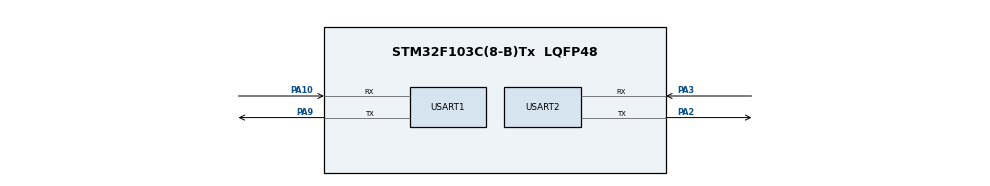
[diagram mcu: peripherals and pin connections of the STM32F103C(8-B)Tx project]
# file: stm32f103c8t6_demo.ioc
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Mcu.Family=STM32F1
Dma.USART2_RX.2.PeriphDataAlignment=DMA_PDATAALIGN_BYTE
Dma.USART2_TX.3.MemDataAlignment=DMA_MDATAALIGN_BYTE
NVIC.DMA1_Channel6_IRQn=true\:0\:0\:false\:false\:true\:false\:true
Dma.USART1_TX.1.Instance=DMA1_Channel4
NVIC.DMA1_Channel5_IRQn=true\:0\:0\:false\:false\:true\:false\:true
Dma.USART1_RX.0.PeriphDataAlignment=DMA_PDATAALIGN_BYTE
PA10.Mode=Asynchronous
Dma.USART1_TX.1.MemInc=DMA_MINC_ENABLE
Dma.USART2_TX.3.Instance=DMA1_Channel7
Dma.USART2_TX.3.MemInc=DMA_MINC_ENABLE
Dma.USART2_TX.3.PeriphInc=DMA_PINC_DISABLE
Dma.USART2_TX.3.Direction=DMA_MEMORY_TO_PERIPH
VP_SYS_VS_ND.Mode=No_Debug
NVIC.USART2_IRQn=true\:0\:0\:false\:false\:true\:true\:true
Dma.USART2_RX.2.Mode=DMA_NORMAL
ProjectManager.StackSize=0x400
PA3.Mode=Asynchronous
PA9.Mode=Asynchronous
TIM1.Prescaler=800-1
Dma.USART2_RX.2.MemInc=DMA_MINC_ENABLE
ProjectManager.TargetToolchain=MDK-ARM V5
Dma.USART1_RX.0.Direction=DMA_PERIPH_TO_MEMORY
RCC.HCLKFreq_Value=8000000
RCC.APB2TimFreq_Value=8000000
PA9.Signal=USART1_TX
Dma.USART2_RX.2.Priority=DMA_PRIORITY_LOW
Dma.USART2_TX.3.PeriphDataAlignment=DMA_PDATAALIGN_BYTE
Dma.USART2_RX.2.MemDataAlignment=DMA_MDATAALIGN_BYTE
RCC.AHBFreq_Value=8000000
Dma.USART1_RX.0.PeriphInc=DMA_PINC_DISABLE
Dma.USART1_RX.0.Priority=DMA_PRIORITY_MEDIUM
Dma.USART1_TX.1.MemDataAlignment=DMA_MDATAALIGN_BYTE
board=custom
Dma.USART2_RX.2.PeriphInc=DMA_PINC_DISABLE
RCC.APB2Freq_Value=8000000
VP_TIM2_VS_ClockSourceINT.Mode=Internal
Dma.USART2_TX.3.Mode=DMA_NORMAL
Dma.USART1_RX.0.MemDataAlignment=DMA_MDATAALIGN_BYTE
TIM2.Period=100-1
Dma.USART1_RX.0.MemInc=DMA_MINC_ENABLE
Mcu.Name=STM32F103C(8-B)Tx
VP_TIM1_VS_ClockSourceINT.Mode=Internal
Dma.USART1_TX.1.PeriphDataAlignment=DMA_PDATAALIGN_BYTE
PA2.Signal=USART2_TX
Mcu.Package=LQFP48
TIM2.Prescaler=800-1
Dma.USART2_RX.2.Instance=DMA1_Channel6
USART2.VirtualMode=VM_ASYNC
Dma.USART1_TX.1.Mode=DMA_NORMAL
USART1.VirtualMode=VM_ASYNC
PA10.Signal=USART1_RX
ProjectManager.HeapSize=0x200
Dma.USART1_TX.1.PeriphInc=DMA_PINC_DISABLE
Dma.USART2_RX.2.Direction=DMA_PERIPH_TO_MEMORY
Dma.USART2_TX.3.Priority=DMA_PRIORITY_LOW
NVIC.PriorityGroup=NVIC_PRIORITYGROUP_4
Dma.Request2=USART2_RX
Dma.Request1=USART1_TX
RCC.APB1TimFreq_Value=8000000
PA2.Mode=Asynchronous
Dma.Request3=USART2_TX
Dma.USART1_RX.0.Mode=DMA_NORMAL
Dma.USART1_TX.1.Priority=DMA_PRIORITY_MEDIUM
NVIC.DMA1_Channel7_IRQn=true\:0\:0\:false\:false\:true\:false\:true
TIM1.Period=1000-1
NVIC.DMA1_Channel4_IRQn=true\:0\:0\:false\:false\:true\:false\:true
NVIC.USART1_IRQn=true\:0\:0\:false\:false\:true\:true\:true
Dma.Request0=USART1_RX
RCC.APB1Freq_Value=8000000
Dma.USART1_RX.0.Instance=DMA1_Channel5
PA3.Signal=USART2_RX
Dma.USART1_TX.1.Direction=DMA_MEMORY_TO_PERIPH

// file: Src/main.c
/* USER CODE BEGIN Header */
/**
  ******************************************************************************
  * @file           : main.c
  * @brief          : Main program body
  ******************************************************************************
  * @attention
  *
  * <h2><center>&copy; Copyright (c) 2021 STMicroelectronics.
  * All rights reserved.</center></h2>
  *
  * This software component is licensed by ST under BSD 3-Clause license,
  * the "License"; You may not use this file except in compliance with the
  * License. You may obtain a copy of the License at:
  *                        opensource.org/licenses/BSD-3-Clause
  *
  ******************************************************************************
  */
/* USER CODE END Header */

#include "main.h"
#include "dma.h"
#include "tim.h"
#include "usart.h"
#include "gpio.h"

void SystemClock_Config(void);

int main(void)
{

  /* MCU Configuration--------------------------------------------------------*/

  /* Reset of all peripherals, Initializes the Flash interface and the Systick. */
  HAL_Init();

  /* Configure the system clock */
  SystemClock_Config();

  /* Initialize all configured peripherals */
  MX_GPIO_Init();
  MX_DMA_Init();
  MX_TIM1_Init();
  MX_TIM2_Init();
  MX_USART1_UART_Init();
  MX_USART2_UART_Init();
  /* USER CODE BEGIN 2 */
	//();
	HAL_TIM_Base_Start_IT(&htim1);
	HAL_TIM_Base_Start_IT(&htim2);
  /* USER CODE END 2 */

  /* Infinite loop */
  while (1)
  {

    /* USER CODE BEGIN 3 */

//		printf("2222\r\n");
//		HAL_Delay(1000);
//		printf("333333333333333\r\n");
		uint16_t send_len = 700;
		const uint16_t DELAY_TIME = 50;
		for(uint8_t i = 0; i < 10;i++){
			memset(uart1_tx_buff, i+47, UART1_BUFF_SIZE);
			for(uint16_t j = 0; j < send_len; j++){
					if(j % 100 == 0){
						uart1_tx_buff[j] = '\n';
					}
			}
			HAL_UART_Transmit_DMA(&huart1, uart1_tx_buff, send_len);
			HAL_Delay(DELAY_TIME);
			HAL_UART_Transmit(&huart2, uart1_tx_buff, 10, 1000);
		}

  }

  /* USER CODE END 3 */
}

void SystemClock_Config(void)
{
  RCC_OscInitTypeDef RCC_OscInitStruct = {0};
  RCC_ClkInitTypeDef RCC_ClkInitStruct = {0};

  /** Initializes the CPU, AHB and APB busses clocks
  */
  RCC_OscInitStruct.OscillatorType = RCC_OSCILLATORTYPE_HSI;
  RCC_OscInitStruct.HSIState = RCC_HSI_ON;
  RCC_OscInitStruct.HSICalibrationValue = RCC_HSICALIBRATION_DEFAULT;
  RCC_OscInitStruct.PLL.PLLState = RCC_PLL_NONE;
  if (HAL_RCC_OscConfig(&RCC_OscInitStruct) != HAL_OK)
  {
    Error_Handler();
  }
  /** Initializes the CPU, AHB and APB busses clocks
  */
  RCC_ClkInitStruct.ClockType = RCC_CLOCKTYPE_HCLK|RCC_CLOCKTYPE_SYSCLK
                              |RCC_CLOCKTYPE_PCLK1|RCC_CLOCKTYPE_PCLK2;
  RCC_ClkInitStruct.SYSCLKSource = RCC_SYSCLKSOURCE_HSI;
  RCC_ClkInitStruct.AHBCLKDivider = RCC_SYSCLK_DIV1;
  RCC_ClkInitStruct.APB1CLKDivider = RCC_HCLK_DIV1;
  RCC_ClkInitStruct.APB2CLKDivider = RCC_HCLK_DIV1;

  if (HAL_RCC_ClockConfig(&RCC_ClkInitStruct, FLASH_LATENCY_0) != HAL_OK)
  {
    Error_Handler();
  }
}

void Error_Handler(void)
{
}

/************************ (C) COPYRIGHT STMicroelectronics *****END OF FILE****/
